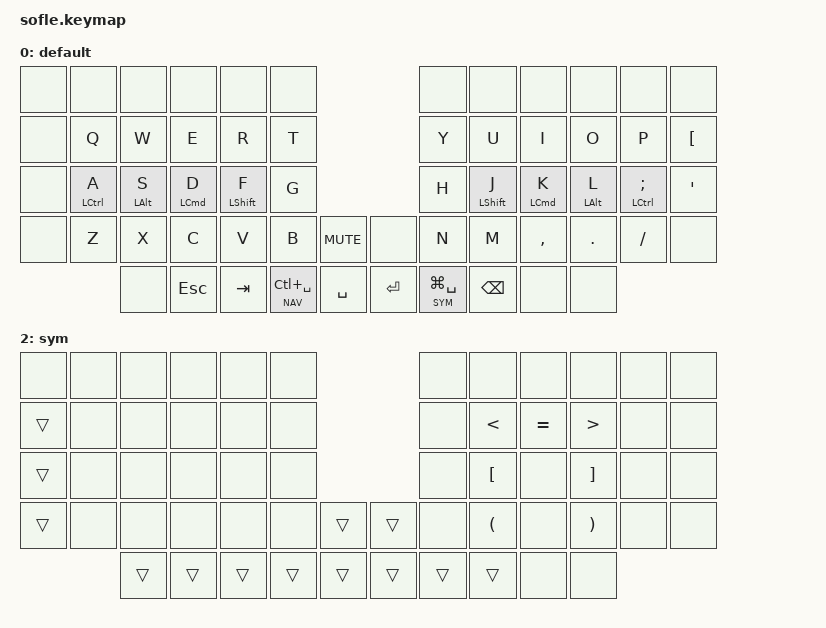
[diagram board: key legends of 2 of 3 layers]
/*
 * Copyright (c) 2020 The ZMK Contributors
 *
 * SPDX-License-Identifier: MIT
 */

#include <behaviors.dtsi>
#include <dt-bindings/zmk/bt.h>
#include <dt-bindings/zmk/ext_power.h>
#include <dt-bindings/zmk/keys.h>
#include <dt-bindings/zmk/rgb.h>

#define BASE 0
#define NAV 1
#define SYM 2
/ {
    behaviors {
        hrm: home_row_mod {
            compatible = "zmk,behavior-hold-tap";
            label = "HOME_ROW_MOD";
            #binding-cells = <2>;
            tapping-term-ms = <180>;
            quick-tap-ms = <120>;
            require-prior-idle-ms = <100>;
            flavor = "tap-preferred";
            bindings = <&kp>, <&kp>;
        };
    };

    keymap {
        compatible = "zmk,keymap";

        default_layer {
            display-name = "default";

            bindings = <
            &none               &none               &none               &none               &none               &none                                                       &none               &none               &none               &none               &none               &none
            &none               &kp Q               &kp W               &kp E               &kp R               &kp T                                                       &kp Y               &kp U               &kp I               &kp O               &kp P               &kp LEFT_BRACKET
            &none               &hrm LCTRL A        &hrm LALT S         &hrm LCMD D         &hrm LSHIFT F       &kp G                                                       &kp H               &hrm LSHIFT J       &hrm LCMD K         &hrm LALT L         &hrm LCTRL SEMI     &kp SQT
            &none               &kp Z               &kp X               &kp C               &kp V               &kp B               &kp C_MUTE          &none               &kp N               &kp M               &kp COMMA           &kp DOT             &kp FSLH            &none
                                                    &none               &kp ESC             &kp TAB             &lt NAV LC(SPACE)   &kp SPACE           &kp ENTER           &lt SYM LG(SPACE)   &kp BKSP            &none               &none
            >;

            sensor-bindings =
                <&inc_dec_kp C_VOL_UP C_VOL_DN>;
        };

       nav_num_layer {
           display-name = "nav_num";
           
           bindings = <
           &none                &none               &none               &none               &none               &none                                                       &none               &none               &none               &none               &none               &none
           &trans               &none               &kp HOME            &kp UP              &kp END             &none                                                       &none               &kp N7              &kp N8              &kp N9              &kp ASTERISK        &mt PERCENT KP_DIVIDE
           &trans               &hrm LCTRL &none    &hrm LALT LEFT      &hrm LCMD DOWN      &hrm LSHIFT RIGHT   &none                                                       &none               &hrm LSHIFT N4      &hrm LCMD N5        &hrm LALT N6        &hrm LCTRL EQUAL    &kp MINUS
           &trans               &none               &kp LA(LEFT)        &none               &kp LA(RIGHT)       &none               &trans              &trans              &none               &kp N1              &kp N2              &kp N3              &none               &none
                                                    &trans              &trans              &trans              &trans              &trans              &trans              &trans              &trans              &kp N0              &none
            >;
        };

        sym_layer {
            display-name = "sym";

            bindings = <
            &none               &none               &none               &none               &none               &none                                                       &none               &none               &none               &none               &none               &none
            &trans              &none               &none               &none               &none               &none                                                       &none               &kp LT              &kp EQUAL           &kp GT              &none               &none
            &trans              &none               &none               &none               &none               &none                                                       &none               &kp LBKT            &none               &kp RBKT            &none               &none
            &trans              &none               &none               &none               &none               &none               &trans              &trans              &none               &kp LPAR            &none               &kp RPAR            &none               &none
                                                    &trans              &trans              &trans              &trans              &trans              &trans              &trans              &trans              &none               &none
            >;
        };
    };
};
